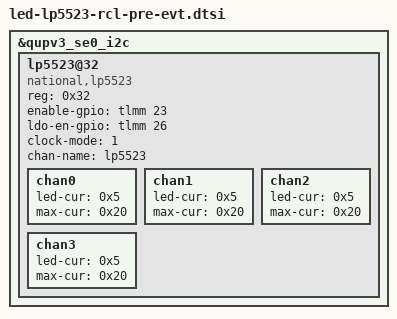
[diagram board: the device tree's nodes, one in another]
&qupv3_se0_i2c {
	status = "ok";
	lp5523@32 {
		compatible = "national,lp5523";
		reg = <0x32>;
		enable-gpio = <&tlmm 23 0x00>;
		ldo-en-gpio = <&tlmm 26 0x00>;
		//trig-gpio = <&tlmm 21 0x00>;
		//int-gpio = <&tlmm 75 0x2008>;
		//pinctrl-names = "lp55xx_active","lp55xx_suspend";
		//pinctrl-0 = <&lp55xx_enble_active>;
		//pinctrl-1 = <&lp55xx_enble_suspend>;
		clock-mode = /bits/ 8 <1>;
		chan-name = "lp5523";

		chan0 {
				led-cur = /bits/ 8 <0x5>;
				max-cur = /bits/ 8 <0x20>;
		};

		chan1 {
				led-cur = /bits/ 8 <0x5>;
				max-cur = /bits/ 8 <0x20>;
		};

		chan2 {
				led-cur = /bits/ 8 <0x5>;
				max-cur = /bits/ 8 <0x20>;
		};

		chan3 {
				led-cur = /bits/ 8 <0x5>;
				max-cur = /bits/ 8 <0x20>;
		};
	};
};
